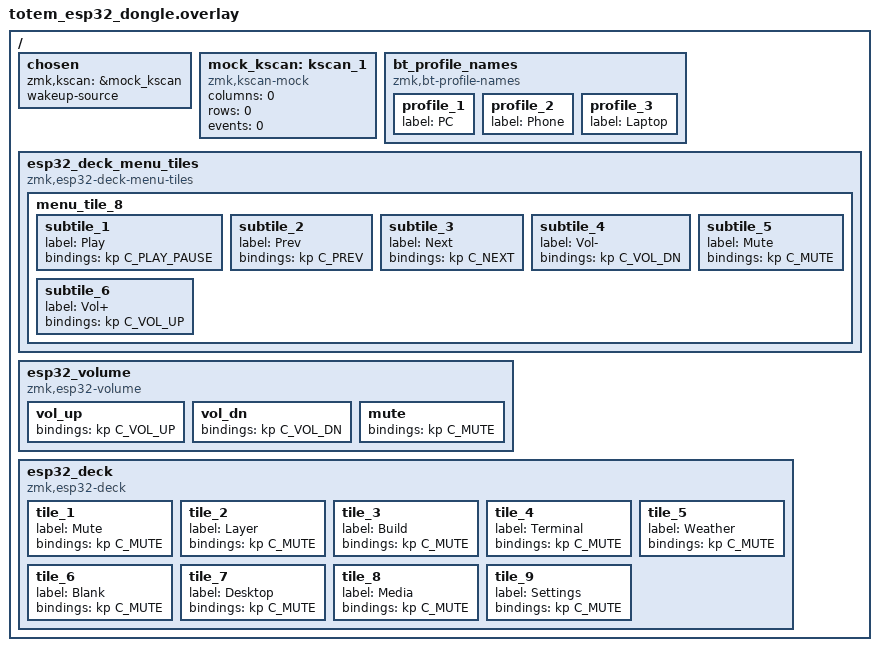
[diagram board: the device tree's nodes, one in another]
/*
 * Copyright (c) 2020 The ZMK Contributors
 *
 * SPDX-License-Identifier: MIT
 */
#include "totem.dtsi"
#include <dt-bindings/zmk/keys.h>
#include <dt-bindings/zmk/bt.h>
#include <dt-bindings/zmk/consumer.h>

/ {
    chosen {
        zmk,kscan = &mock_kscan;
        wakeup-source;
    };

    mock_kscan: kscan_1 {
        compatible = "zmk,kscan-mock";
        columns = <0>;
        rows = <0>;
        events = <0>;
    };
};
 
/*
 * BT profile names for host connections shown on the ESP32 screen.
 * Only define labels for host profiles — peripheral slots are separate
 * and not counted here. For this keyboard:
 *   BT_MAX_PAIRED=5, CENTRAL_PERIPHERALS=2 → 3 host profiles.
 * Adjust if your keyboard has a different number of peripherals.
 */
/ {
    bt_profile_names {
        compatible = "zmk,bt-profile-names";

        profile_1 {
            label = "PC";
        };

        profile_2 {
            label = "Phone";
        };

        profile_3 {
            label = "Laptop";
        };
    };
};

/*
 * Sub-tile bindings for deck tiles marked as "menu tiles" on the ESP32.
 * Add a menu_tile_N node for each parent tile that will be a menu tile,
 * then add subtile_1..subtile_9 children with their bindings and labels.
 * Only tiles configured as menu tiles in the ESP32 settings need entries here.
 */
/ {
    esp32_deck_menu_tiles {
        compatible = "zmk,esp32-deck-menu-tiles";

        menu_tile_8 {
            subtile_1 {
                label = "Play";
                bindings = <&kp C_PLAY_PAUSE>;
            };
            subtile_2 {
                label = "Prev";
                bindings = <&kp C_PREV>;
            };
            subtile_3 {
                label = "Next";
                bindings = <&kp C_NEXT>;
            };
            subtile_4 {
                label = "Vol-";
                bindings = <&kp C_VOL_DN>;
            };
            subtile_5 {
                label = "Mute";
                bindings = <&kp C_MUTE>;
            };
            subtile_6 {
                label = "Vol+";
                bindings = <&kp C_VOL_UP>;
            };
        };
    };
};

/ {
    esp32_volume {
        compatible = "zmk,esp32-volume";
        vol_up { bindings = <&kp C_VOL_UP>; };
        vol_dn { bindings = <&kp C_VOL_DN>; };
        mute   { bindings = <&kp C_MUTE>; };
    };
};

/ {
    esp32_deck {
        compatible = "zmk,esp32-deck";

        tile_1 {
            label = "Mute";
            bindings = <&kp C_MUTE>;
        };

        tile_2 {
            label = "Layer";
            bindings = <&kp C_MUTE>;
        };

        tile_3 {
            label = "Build";
            bindings = <&kp C_MUTE>;
        };

        tile_4 {
            label = "Terminal";
            bindings = <&kp C_MUTE>;
        };

        tile_5 {
            label = "Weather";
            bindings = <&kp C_MUTE>;
        };

        tile_6 {
            label = "Blank";
            bindings = <&kp C_MUTE>;
        };

        tile_7 {
            label = "Desktop";
            bindings = <&kp C_MUTE>;
        };

        tile_8 {
            label = "Media";
            bindings = <&kp C_MUTE>;
        };

        tile_9 {
            label = "Settings";
            bindings = <&kp C_MUTE>;
        };
    };
};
